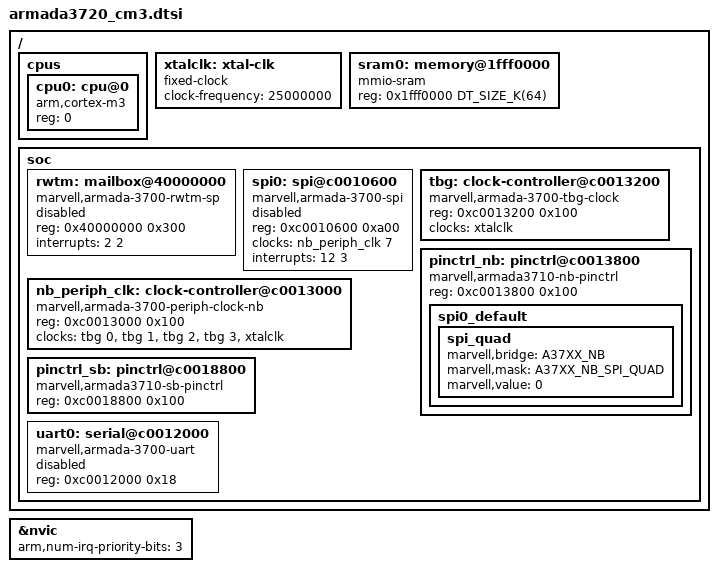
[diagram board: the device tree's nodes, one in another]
/*
 * Copyright (c) 2026 Jiri Kastner
 *
 * SPDX-License-Identifier: Apache-2.0
 *
 * Armada 3720 Cortex-M3 secure processor. Its view of the address map:
 * SRAM at 0x1fff0000 (code, data and stack of the WTMI image), own
 * registers at 0x40000000, SoC registers at 0xc0000000 (0xd0000000 for
 * the A53), DDR at 0x60000000.
 *
 * NVIC lines (CZ.NIC mox-boot-builder wtmi/irq.h): 0 AP, 1 USB, 2 SP
 * (A53 mailbox command), 3 DMA, 4 MCT, 5 BCM access error, 6 EC ZMODP,
 * 7 hash, 8 SATA, 9 crypto, 10 eMMC/SDIO, 11 SPAD, 12 SPI, 13 UART RX,
 * 14/15 CTI trigger out. No I2C line; the UART has no TX interrupt, so
 * it stays polled.
 */

#include <arm/armv7-m.dtsi>
#include <mem.h>
#include <zephyr/dt-bindings/pinctrl/armada37xx-pinctrl.h>

/ {
	cpus {
		#address-cells = <1>;
		#size-cells = <0>;

		cpu0: cpu@0 {
			device_type = "cpu";
			compatible = "arm,cortex-m3";
			reg = <0>;
		};
	};

	xtalclk: xtal-clk {
		compatible = "fixed-clock";
		clock-frequency = <25000000>;
		#clock-cells = <0>;
	};

	/* 64 KiB below 0x20000000; the BootROM keeps the TIM at 0x20006000 */
	sram0: memory@1fff0000 {
		compatible = "mmio-sram";
		reg = <0x1fff0000 DT_SIZE_K(64)>;
	};

	soc {
		/* the A53 commands: rWTM mailbox, secure processor side */
		rwtm: mailbox@40000000 {
			compatible = "marvell,armada-3700-rwtm-sp";
			reg = <0x40000000 0x300>;
			interrupts = <2 2>;
			#mbox-cells = <1>;
			status = "disabled";
		};

		/* SPI NOR controller, NVIC line 12 */
		spi0: spi@c0010600 {
			compatible = "marvell,armada-3700-spi";
			reg = <0xc0010600 0xa00>;
			#address-cells = <1>;
			#size-cells = <0>;
			/* sqf */
			clocks = <&nb_periph_clk 7>;
			interrupts = <12 3>;
			status = "disabled";
		};

		nb_periph_clk: clock-controller@c0013000 {
			compatible = "marvell,armada-3700-periph-clock-nb";
			reg = <0xc0013000 0x100>;
			clocks = <&tbg 0>, <&tbg 1>, <&tbg 2>, <&tbg 3>, <&xtalclk>;
			#clock-cells = <1>;
		};

		tbg: clock-controller@c0013200 {
			compatible = "marvell,armada-3700-tbg-clock";
			reg = <0xc0013200 0x100>;
			clocks = <&xtalclk>;
			#clock-cells = <1>;
		};

		pinctrl_nb: pinctrl@c0013800 {
			compatible = "marvell,armada3710-nb-pinctrl";
			reg = <0xc0013800 0x100>;
		};

		pinctrl_sb: pinctrl@c0018800 {
			compatible = "marvell,armada3710-sb-pinctrl";
			reg = <0xc0018800 0x100>;
		};

		uart0: serial@c0012000 {
			compatible = "marvell,armada-3700-uart";
			reg = <0xc0012000 0x18>;
			status = "disabled";
		};
	};
};

&nvic {
	arm,num-irq-priority-bits = <3>;
};

&pinctrl_nb {
	/* CLK, MOSI, MISO and CS0 are dedicated; IO2/IO3 (WP#/HOLD#) are muxed */
	spi0_default: spi0_default {
		spi_quad {
			marvell,bridge = <A37XX_NB>;
			marvell,mask = <A37XX_NB_SPI_QUAD>;
			marvell,value = <0>;
		};
	};
};
